# B6x register map
Vendor: XiaoMan; Series: B6 SOC; File version: 20260307
CPU: CM0+ r0p0, little endian, no MPU, no FPU, 2 interrupt priority bits
Registers are 32-bit, read-write, reset 0x0 unless marked. A register's access mark holds for its fields unless they carry their own. Offsets are from the block's base; [hi:lo] are bit positions; {n}, {i} and the like mark numbered series.

## CSC
Base 0x40002000
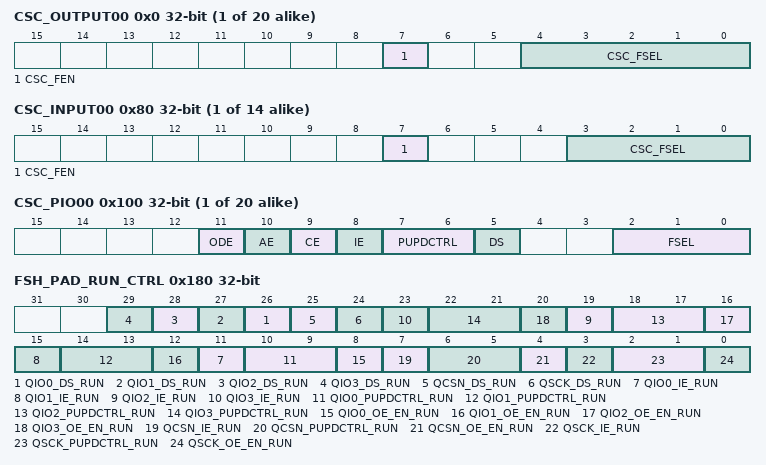
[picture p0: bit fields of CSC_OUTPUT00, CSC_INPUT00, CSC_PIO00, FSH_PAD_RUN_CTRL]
{0x0+4i} CSC_OUTPUT{i:02} (i=0..19)
  [7] CSC_FEN — csc peripheral function enable
  [4:0] CSC_FSEL — pad output function select
{0x80+4i} CSC_INPUT{i:02} (i=0..13)
  [7] CSC_FEN — csc peripheral function enable
  [3:0] CSC_FSEL — pad input function select
{0x100+4i} CSC_PIO{i:02} (i=0..19)
  [11] ODE — open drain enable
  [10] AE — analog enable
  [9] CE — 1ma current spurce enable
  [8] IE — input enable
  [7:6] PUPDCTRL — pull up/down
  [5] DS — drive strength mode
  [2:0] FSEL — function select
0x180 FSH_PAD_RUN_CTRL
  [n+26] QIO{n}_DS_RUN (n=0..3) — QIO{n} drive strength
  [25] QCSN_DS_RUN — QCSN drive strength
  [24] QSCK_DS_RUN — QSCK drive strength
  [4n+11] QIO{n}_IE_RUN (n=0..3) — QIO{n} input enable
  [4n+10:4n+9] QIO{n}_PUPDCTRL_RUN (n=0..3) — QIO{n} Pull Up and Pull Down
  [4n+8] QIO{n}_OE_EN_RUN (n=0..3) — QIO{n} Output enable
  [7] QCSN_IE_RUN — QCSN input enable
  [6:5] QCSN_PUPDCTRL_RUN — QCSN Pull Up and Pull Down
  [4] QCSN_OE_EN_RUN — QCSN Output enable
  [3] QSCK_IE_RUN — QSCK input enable
  [2:1] QSCK_PUPDCTRL_RUN — QSCK Pull Up and Pull Down
  [0] QSCK_OE_EN_RUN — QSCK Output enable
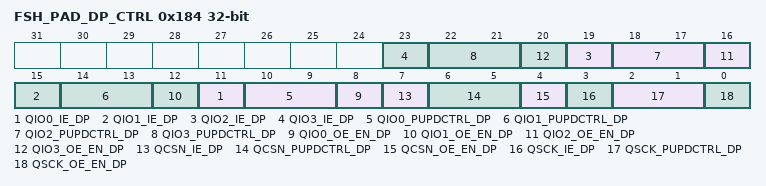
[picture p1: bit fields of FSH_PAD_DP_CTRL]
0x184 FSH_PAD_DP_CTRL
  [4n+11] QIO{n}_IE_DP (n=0..3) — QIO{n} input enable
  [4n+10:4n+9] QIO{n}_PUPDCTRL_DP (n=0..3) — QIO{n} Pull Up and Pull Down
  [4n+8] QIO{n}_OE_EN_DP (n=0..3) — QIO{n} Output enable
  [7] QCSN_IE_DP — QCSN input enable
  [6:5] QCSN_PUPDCTRL_DP — QCSN Pull Up and Pull Down
  [4] QCSN_OE_EN_DP — QCSN Output enable
  [3] QSCK_IE_DP — QSCK input enable
  [2:1] QSCK_PUPDCTRL_DP — QSCK Pull Up and Pull Down
  [0] QSCK_OE_EN_DP — QSCK Output enable

## GPIO
Base 0x40010000
0x00 DAT_SET
0x04 DAT_CLR
0x08 DAT_TOG
0x0C DAT_MSK
0x10 DAT
0x14 PIN
0x20 DIR_SET
0x24 DIR_CLR
0x28 DIR_TOG
0x2C DIR_MSK
0x30 DIR

## I2C — IIC
Base 0x40029000
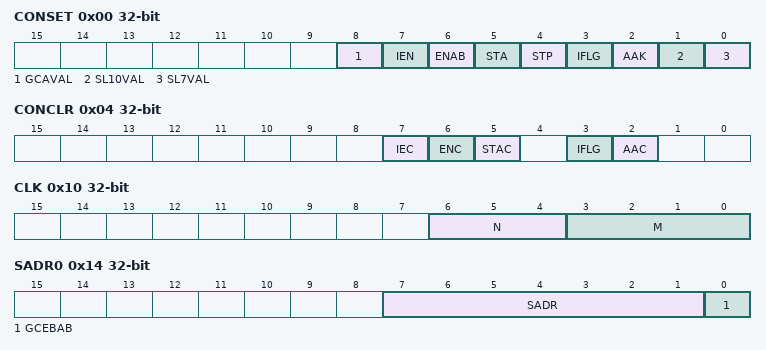
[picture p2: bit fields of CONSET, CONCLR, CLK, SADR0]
0x00 CONSET — i2c control reg
  [8] GCAVAL
  [7] IEN — i2c interrupt Enable or Disable
  [6] ENAB — I2C Enable or Disable
  [5] STA
  [4] STP
  [3] IFLG — flag signal
  [2] AAK
  [1] SL10VAL — 10-bit address control bit
  [0] SL7VAL — 7-bit address control bit
0x04 CONCLR — i2c control clr register
  [7] IEC
  [6] ENC
  [5] STAC
  [3] IFLG — flag signal
  [2] AAC
0x08 SR — i2c status reg
  [7:3] STATUS — i2c status
0x0C DATA
  [7:0] DATA
0x10 CLK — i2c clock (scl) speed contorl register
  [6:4] N — i2c samp frequency
  [3:0] M — i2c master mode scl frequency
0x14 SADR0 — slaver address register
  [7:1] SADR — v
  [0] GCEBAB
0x18 ADM0
  [7:1] ADM0
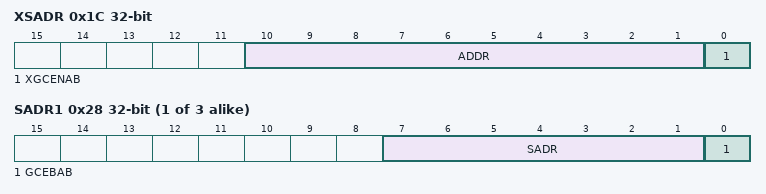
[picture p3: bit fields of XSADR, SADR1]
0x1C XSADR — extension slaver address register
  [10:1] ADDR, [0] XGCENAB
0x20 XADM
  [10:1] XADM0
0x24 SRST
{0x20+8i} SADR{i} (i=1..3) — slaver address{i} register
  [7:1] SADR, [0] GCEBAB
0x2C ADM1
  [7:1] MASK
0x34 ADM2
  [7:1] MASK
0x3C ADM3 — ADM2 register
  [7:1] MASK

## ADC
Base 0x40007000
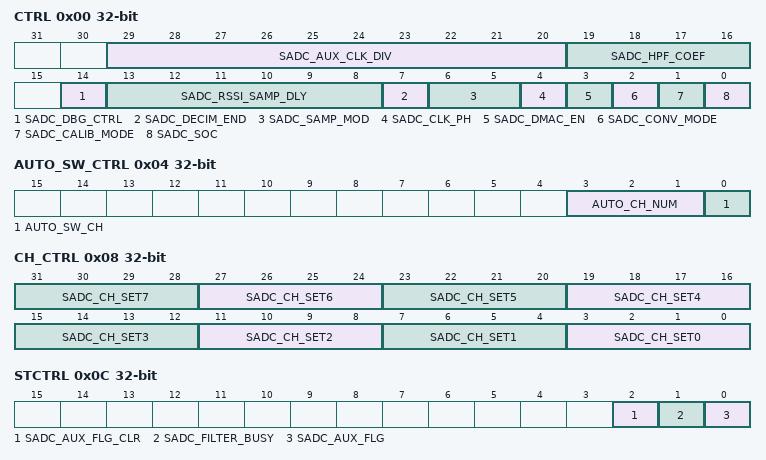
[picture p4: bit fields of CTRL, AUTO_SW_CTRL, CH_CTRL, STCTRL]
0x00 CTRL
  [29:20] SADC_AUX_CLK_DIV — adc function clock = hclk / (sadc_aux_clk_div + 1 )
  [19:16] SADC_HPF_COEF — decimation filter high pass filter coef
  [14] SADC_DBG_CTRL
  [13:8] SADC_RSSI_SAMP_DLY — delay time from rssi_req to SADC sample RSSI
  [7] SADC_DECIM_END
  [6:5] SADC_SAMP_MOD
  [4] SADC_CLK_PH
  [3] SADC_DMAC_EN
  [2] SADC_CONV_MODE
  [1] SADC_CALIB_MODE
  [0] SADC_SOC
0x04 AUTO_SW_CTRL
  [3:1] AUTO_CH_NUM
  [0] AUTO_SW_CH — when is 1, ADC_VIN_SEL is auto change
0x08 CH_CTRL
  [4n+3:4n] SADC_CH_SET{n} (n=0..7)
0x0C STCTRL
  [2] SADC_AUX_FLG_CLR, [1] SADC_FILTER_BUSY, [0] SADC_AUX_FLG
0x10 DC_OFFSET
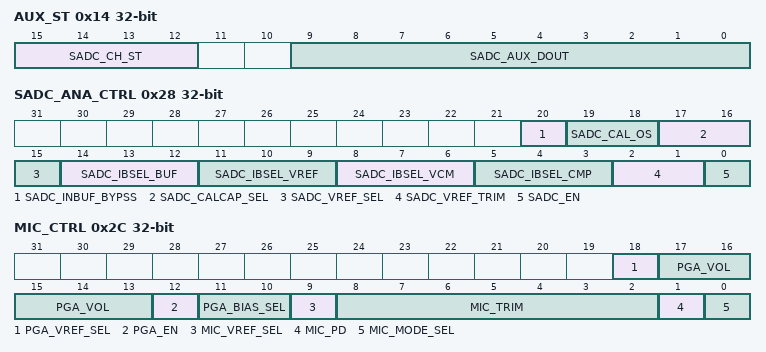
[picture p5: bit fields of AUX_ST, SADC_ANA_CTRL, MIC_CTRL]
0x14 AUX_ST
  [15:12] SADC_CH_ST, [9:0] SADC_AUX_DOUT
0x18 PCM_DAT
0x1C SADC_CALIB_DATIN
0x20 SADC_CALIB_DATSEL
0x24 SADC_CALIB_DATOUT
0x28 SADC_ANA_CTRL
  [20] SADC_INBUF_BYPSS, [19:18] SADC_CAL_OS, [17:16] SADC_CALCAP_SEL, [15] SADC_VREF_SEL, [14:12] SADC_IBSEL_BUF, [11:9] SADC_IBSEL_VREF, [8:6] SADC_IBSEL_VCM, [5:3] SADC_IBSEL_CMP, [2:1] SADC_VREF_TRIM, [0] SADC_EN
0x2C MIC_CTRL
  [18] PGA_VREF_SEL, [17:13] PGA_VOL, [12] PGA_EN, [11:10] PGA_BIAS_SEL, [9] MIC_VREF_SEL, [8:2] MIC_TRIM, [1] MIC_PD, [0] MIC_MODE_SEL
